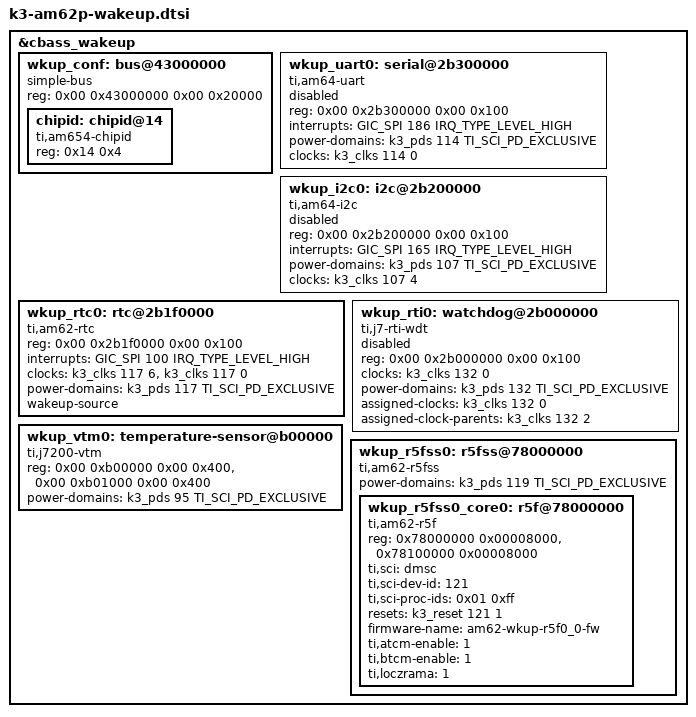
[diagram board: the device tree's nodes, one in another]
// SPDX-License-Identifier: GPL-2.0
/*
 * Device Tree file for the AM62P wakeup domain peripherals
 * Copyright (C) 2023 Texas Instruments Incorporated - https://www.ti.com/
 */

&cbass_wakeup {
	wkup_conf: bus@43000000 {
		compatible = "simple-bus";
		reg = <0x00 0x43000000 0x00 0x20000>;
		#address-cells = <1>;
		#size-cells = <1>;
		ranges = <0x00 0x00 0x43000000 0x20000>;
		bootph-all;

		chipid: chipid@14 {
			compatible = "ti,am654-chipid";
			reg = <0x14 0x4>;
			bootph-all;
		};
	};

	wkup_uart0: serial@2b300000 {
		compatible = "ti,am64-uart", "ti,am654-uart";
		reg = <0x00 0x2b300000 0x00 0x100>;
		interrupts = <GIC_SPI 186 IRQ_TYPE_LEVEL_HIGH>;
		power-domains = <&k3_pds 114 TI_SCI_PD_EXCLUSIVE>;
		clocks = <&k3_clks 114 0>;
		clock-names = "fclk";
		status = "disabled";
	};

	wkup_i2c0: i2c@2b200000 {
		compatible = "ti,am64-i2c", "ti,omap4-i2c";
		reg = <0x00 0x2b200000 0x00 0x100>;
		interrupts = <GIC_SPI 165 IRQ_TYPE_LEVEL_HIGH>;
		#address-cells = <1>;
		#size-cells = <0>;
		power-domains = <&k3_pds 107 TI_SCI_PD_EXCLUSIVE>;
		clocks = <&k3_clks 107 4>;
		clock-names = "fck";
		status = "disabled";
	};

	wkup_rtc0: rtc@2b1f0000 {
		compatible = "ti,am62-rtc";
		reg = <0x00 0x2b1f0000 0x00 0x100>;
		interrupts = <GIC_SPI 100 IRQ_TYPE_LEVEL_HIGH>;
		clocks = <&k3_clks 117 6> , <&k3_clks 117 0>;
		clock-names = "vbus", "osc32k";
		power-domains = <&k3_pds 117 TI_SCI_PD_EXCLUSIVE>;
		wakeup-source;
	};

	wkup_rti0: watchdog@2b000000 {
		compatible = "ti,j7-rti-wdt";
		reg = <0x00 0x2b000000 0x00 0x100>;
		clocks = <&k3_clks 132 0>;
		power-domains = <&k3_pds 132 TI_SCI_PD_EXCLUSIVE>;
		assigned-clocks = <&k3_clks 132 0>;
		assigned-clock-parents = <&k3_clks 132 2>;
		/* Used by DM firmware */
		status = "reserved";
	};

	wkup_vtm0: temperature-sensor@b00000 {
		compatible = "ti,j7200-vtm";
		reg = <0x00 0xb00000 0x00 0x400>,
		      <0x00 0xb01000 0x00 0x400>;
		power-domains = <&k3_pds 95 TI_SCI_PD_EXCLUSIVE>;
		#thermal-sensor-cells = <1>;
	};

	wkup_r5fss0: r5fss@78000000 {
		compatible = "ti,am62-r5fss";
		#address-cells = <1>;
		#size-cells = <1>;
		ranges = <0x78000000 0x00 0x78000000 0x8000>,
			 <0x78100000 0x00 0x78100000 0x8000>;
		power-domains = <&k3_pds 119 TI_SCI_PD_EXCLUSIVE>;

		wkup_r5fss0_core0: r5f@78000000 {
			compatible = "ti,am62-r5f";
			reg = <0x78000000 0x00008000>,
			      <0x78100000 0x00008000>;
			reg-names = "atcm", "btcm";
			ti,sci = <&dmsc>;
			ti,sci-dev-id = <121>;
			ti,sci-proc-ids = <0x01 0xff>;
			resets = <&k3_reset 121 1>;
			firmware-name = "am62-wkup-r5f0_0-fw";
			ti,atcm-enable = <1>;
			ti,btcm-enable = <1>;
			ti,loczrama = <1>;
		};
	};
};
